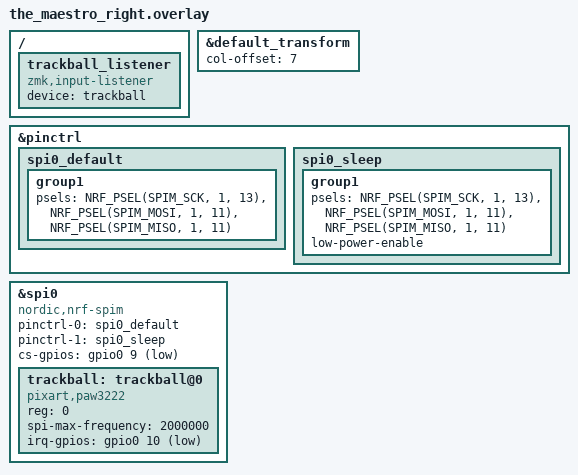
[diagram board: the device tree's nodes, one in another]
#include "the_maestro.dtsi"

&default_transform {
  col-offset = <7>;
};

&pinctrl {
  spi0_default: spi0_default {
    group1 {
      psels = <NRF_PSEL(SPIM_SCK, 1, 13)>,
              <NRF_PSEL(SPIM_MOSI, 1, 11)>,
              <NRF_PSEL(SPIM_MISO, 1, 11)>;
    };
  };

  spi0_sleep: spi0_sleep {
    group1 {
      psels = <NRF_PSEL(SPIM_SCK, 1, 13)>,
              <NRF_PSEL(SPIM_MOSI, 1, 11)>,
              <NRF_PSEL(SPIM_MISO, 1, 11)>;
      low-power-enable;
    };
  };
};

&spi0 {
  status = "okay";
  compatible = "nordic,nrf-spim";
  pinctrl-0 = <&spi0_default>;
  pinctrl-1 = <&spi0_sleep>;
  pinctrl-names = "default", "sleep";
  cs-gpios = <&gpio0 9 GPIO_ACTIVE_LOW>;

  trackball: trackball@0 {
    status = "okay";
    compatible = "pixart,paw3222";
    reg = <0>;
    spi-max-frequency = <2000000>;
    irq-gpios = <&gpio0 10 GPIO_ACTIVE_LOW>;
  };
};

/ {
  trackball_listener: trackball_listener {
    compatible = "zmk,input-listener";
    device = <&trackball>;
  };
};
